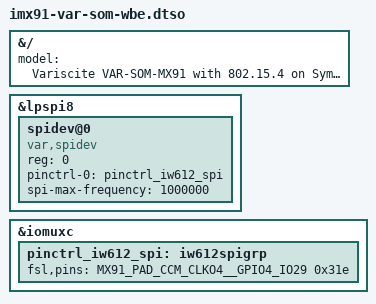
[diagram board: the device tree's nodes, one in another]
// SPDX-License-Identifier: (GPL-2.0+ OR MIT)
/*
 * Device tree overlay to support the VAR-SOM-MX91 featuring
 * WiFi/BT chipset with 802.15.4, used on the Symphony-Board
 *
 * Copyright 2026 Variscite Ltd.
 */

/dts-v1/;
/plugin/;

#include "imx91-pinfunc.h"

&{/} {
	model = "Variscite VAR-SOM-MX91 with 802.15.4 on Symphony-Board v1.x";
};

&lpspi8 {
	#address-cells = <1>;
	#size-cells = <0>;

	/* 802.15.4 SPI device */
	spidev@0 {
		compatible = "var,spidev";
		reg = <0>;
		pinctrl-names = "default";
		pinctrl-0 = <&pinctrl_iw612_spi>;
		spi-max-frequency = <1000000>;
		status = "okay";
	};
};

&iomuxc {
	pinctrl_iw612_spi: iw612spigrp {
		fsl,pins = <
			MX91_PAD_CCM_CLKO4__GPIO4_IO29			0x31e	/* 802.15.4 IRQ */
		>;
	};
};
